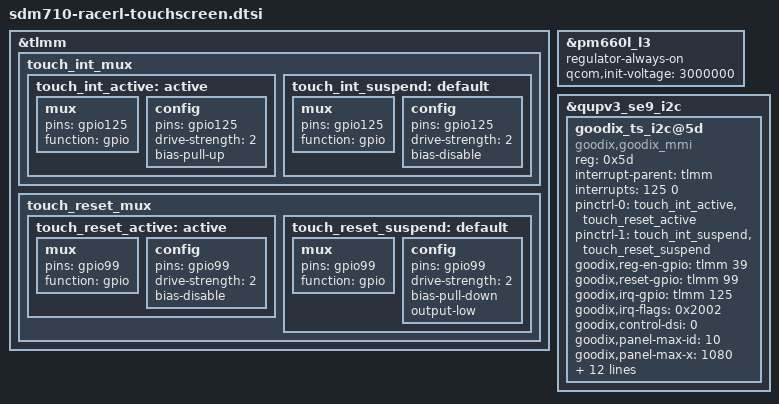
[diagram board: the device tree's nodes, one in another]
&tlmm {
	touch_int_mux {
		touch_int_active: active {
			mux {
				pins = "gpio125";
				function = "gpio";
			};
			config {
				pins = "gpio125";
				drive-strength = <2>;
				bias-pull-up;
			};
		};

		touch_int_suspend: default {
			mux {
				pins = "gpio125";
				function = "gpio";
			};
			config {
				pins = "gpio125";
				drive-strength = <2>;
				bias-disable;
			};
		};
	};

	touch_reset_mux {
		touch_reset_active: active {
			mux {
				pins = "gpio99";
				function = "gpio";
			};
			config {
				pins = "gpio99";
				drive-strength = <2>;
				bias-disable;
			};
		};

		touch_reset_suspend: default {
			mux {
				pins = "gpio99";
				function = "gpio";
			};
			config {
				pins = "gpio99";
				drive-strength = <2>;
				bias-pull-down;
				output-low;
			};
		};
	};
};

&pm660l_l3 {
	regulator-always-on;
	qcom,init-voltage = <3000000>;
};

&qupv3_se9_i2c {
	status = "okay";

	goodix_ts_i2c@5d {
		compatible = "goodix,goodix_mmi";
		reg = <0x5d>;
		status = "ok";
		interrupt-parent = <&tlmm>;
		interrupts = <125 0>;
		pinctrl-names = "pmx_ts_active","pmx_ts_suspend";
		pinctrl-0 = <&touch_int_active &touch_reset_active>;
		pinctrl-1 = <&touch_int_suspend &touch_reset_suspend>;
		goodix,reg-en-gpio = <&tlmm 39 0x0>;
		goodix,reset-gpio = <&tlmm 99 0x0>;
		goodix,irq-gpio = <&tlmm 125 0x2002>;
		goodix,irq-flags = <0x2002>; /* 1:trigger rising, 2:trigger falling;*/
		goodix,control-dsi = <0>;
		goodix,panel-max-id = <10>;
		goodix,panel-max-x = <1080>;
		goodix,panel-max-y = <2340>;
		goodix,panel-max-w = <256>;
		goodix,panel-max-p = <4096>;
		goodix,power-on-delay-us = <300000>; /*300ms*/
		goodix,power-off-delay-us = <5000>;
		/*goodix,swap-axis;*/
		goodix,x2x;
		goodix,y2y;
		goodix,pen-enable;
		goodix,usb_charger;
		goodix,key-of-pen = <331 332>;/*BTN_STYLUS, BTN_STYLUS2*/
		goodix,cfg_bin_name = "goodix_cfg_group2_racerl.bin";
	};
};


